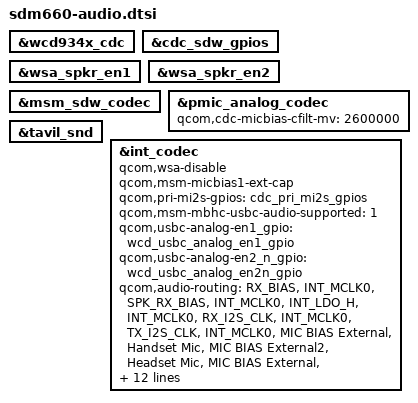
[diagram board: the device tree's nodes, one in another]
&wcd934x_cdc {
	/delete-node/ msm_cdc_pinctrl_usbc_audio_en1;
	/delete-node/ msm_cdc_pinctrl_usbc_audio_en2;
};

&cdc_sdw_gpios {
	/delete-property/ pinctrl-names;
	/delete-property/ pinctrl-0;
	/delete-property/ pinctrl-1;
};

&wsa_spkr_en1 {
	/delete-property/ pinctrl-names;
	/delete-property/ pinctrl-0;
	/delete-property/ pinctrl-1;
};

&wsa_spkr_en2 {
	/delete-property/ pinctrl-names;
	/delete-property/ pinctrl-0;
	/delete-property/ pinctrl-1;
};

&msm_sdw_codec {
	/delete-property/ qcom,cdc-sdw-gpios;
};

&pmic_analog_codec {
	qcom,cdc-micbias-cfilt-mv = <2600000>;
};

&tavil_snd {
	/delete-property/ qcom,usbc-analog-en1_gpio;
	/delete-property/ qcom,usbc-analog-en2_n_gpio;
};

&int_codec {
	qcom,wsa-disable;
	qcom,msm-micbias1-ext-cap;
	/delete-property/ qcom,msm-micbias2-ext-cap;
	/delete-property/ qcom,us-euro-gpios;
	qcom,pri-mi2s-gpios = <&cdc_pri_mi2s_gpios>;
	qcom,msm-mbhc-usbc-audio-supported = <1>;
	qcom,usbc-analog-en1_gpio = <&wcd_usbc_analog_en1_gpio>;
	qcom,usbc-analog-en2_n_gpio = <&wcd_usbc_analog_en2n_gpio>;
	qcom,audio-routing = "RX_BIAS", "INT_MCLK0",
		"SPK_RX_BIAS", "INT_MCLK0",
		"INT_LDO_H", "INT_MCLK0",
		"RX_I2S_CLK", "INT_MCLK0",
		"TX_I2S_CLK", "INT_MCLK0",
		"MIC BIAS External", "Handset Mic",
		"MIC BIAS External2", "Headset Mic",
		"MIC BIAS External", "Secondary Mic",
		"AMIC1", "MIC BIAS External",
		"AMIC2", "MIC BIAS External2",
		"AMIC3", "MIC BIAS External",
		"DMIC1", "MIC BIAS External",
		"MIC BIAS External", "Digital Mic1",
		"DMIC2", "MIC BIAS External",
		"MIC BIAS External", "Digital Mic2",
		"DMIC3", "MIC BIAS External",
		"MIC BIAS External", "Digital Mic3",
		"DMIC4", "MIC BIAS External",
		"MIC BIAS External", "Digital Mic4",
		"PDM_IN_RX1", "PDM_OUT_RX1",
		"PDM_IN_RX2", "PDM_OUT_RX2",
		"PDM_IN_RX3", "PDM_OUT_RX3",
		"ADC1_IN", "ADC1_OUT",
		"ADC2_IN", "ADC2_OUT",
		"ADC3_IN", "ADC3_OUT";
};
